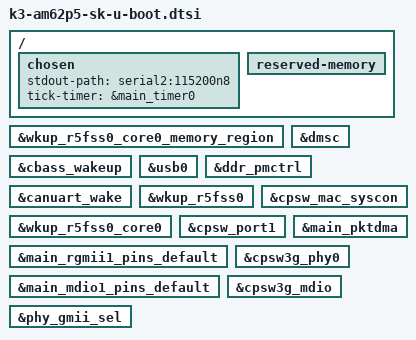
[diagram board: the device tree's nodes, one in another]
// SPDX-License-Identifier: GPL-2.0
/*
 * Common AM62Px EVM dts file for SPLs
 * Copyright (C) 2022 Texas Instruments Incorporated - https://www.ti.com/
 */

#include "k3-am62p-sk-binman.dtsi"

/ {
	chosen {
		stdout-path = "serial2:115200n8";
		tick-timer = &main_timer0;
	};

	reserved-memory {
		bootph-pre-ram;
	};
};

&wkup_r5fss0_core0_memory_region {
	bootph-pre-ram;
};

&cbass_wakeup {
	bootph-pre-ram;
};

&dmsc {
	bootph-pre-ram;
};

/* Required for USB DFU Boot */
&usb0 {
	bootph-all;
};

&ddr_pmctrl {
	bootph-pre-ram;
};

&canuart_wake {
	bootph-pre-ram;
};

&wkup_r5fss0 {
	bootph-pre-ram;
};

&wkup_r5fss0_core0 {
	bootph-pre-ram;
};

&cpsw_mac_syscon {
	bootph-all;
};

&cpsw_port1 {
	bootph-all;
};

&main_pktdma {
	bootph-all;
};

&main_rgmii1_pins_default {
	bootph-all;
};

&main_mdio1_pins_default {
	bootph-all;
};

&cpsw3g_phy0 {
	bootph-all;
};

&cpsw3g_mdio {
	bootph-all;
};

&phy_gmii_sel {
	bootph-all;
};
